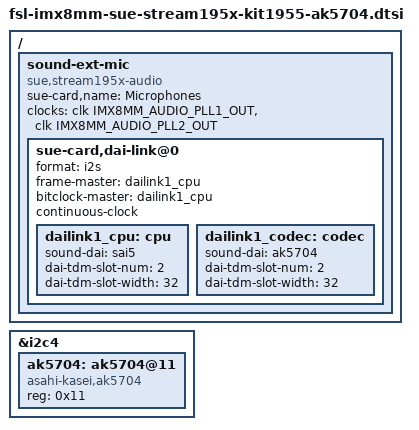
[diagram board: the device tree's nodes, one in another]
// DTSI for original 4-microphone board with AK5704

/ {
	/* Create a new sound card per removable component */
	sound-ext-mic {
		compatible = "sue,stream195x-audio";
		sue-card,name = "Microphones";

		clocks = <&clk IMX8MM_AUDIO_PLL1_OUT>, <&clk IMX8MM_AUDIO_PLL2_OUT>;
		clock-names = "pll8k", "pll11k";

		sue-card,dai-link@0 {
			format = "i2s";

			frame-master = <&dailink1_cpu>;
			bitclock-master = <&dailink1_cpu>;

			continuous-clock;

			dailink1_cpu: cpu {
				sound-dai = <&sai5>;
				dai-tdm-slot-num = <2>;
				dai-tdm-slot-width = <32>;
			};

			dailink1_codec: codec {
				sound-dai = <&ak5704>;
				dai-tdm-slot-num = <2>;
				dai-tdm-slot-width = <32>;
			};
		};
	};
};

&i2c4 {
	ak5704: ak5704@11 {
		compatible = "asahi-kasei,ak5704";
		reg = <0x11>;
		#sound-dai-cells = <0>;
		status = "okay";
	};
};
